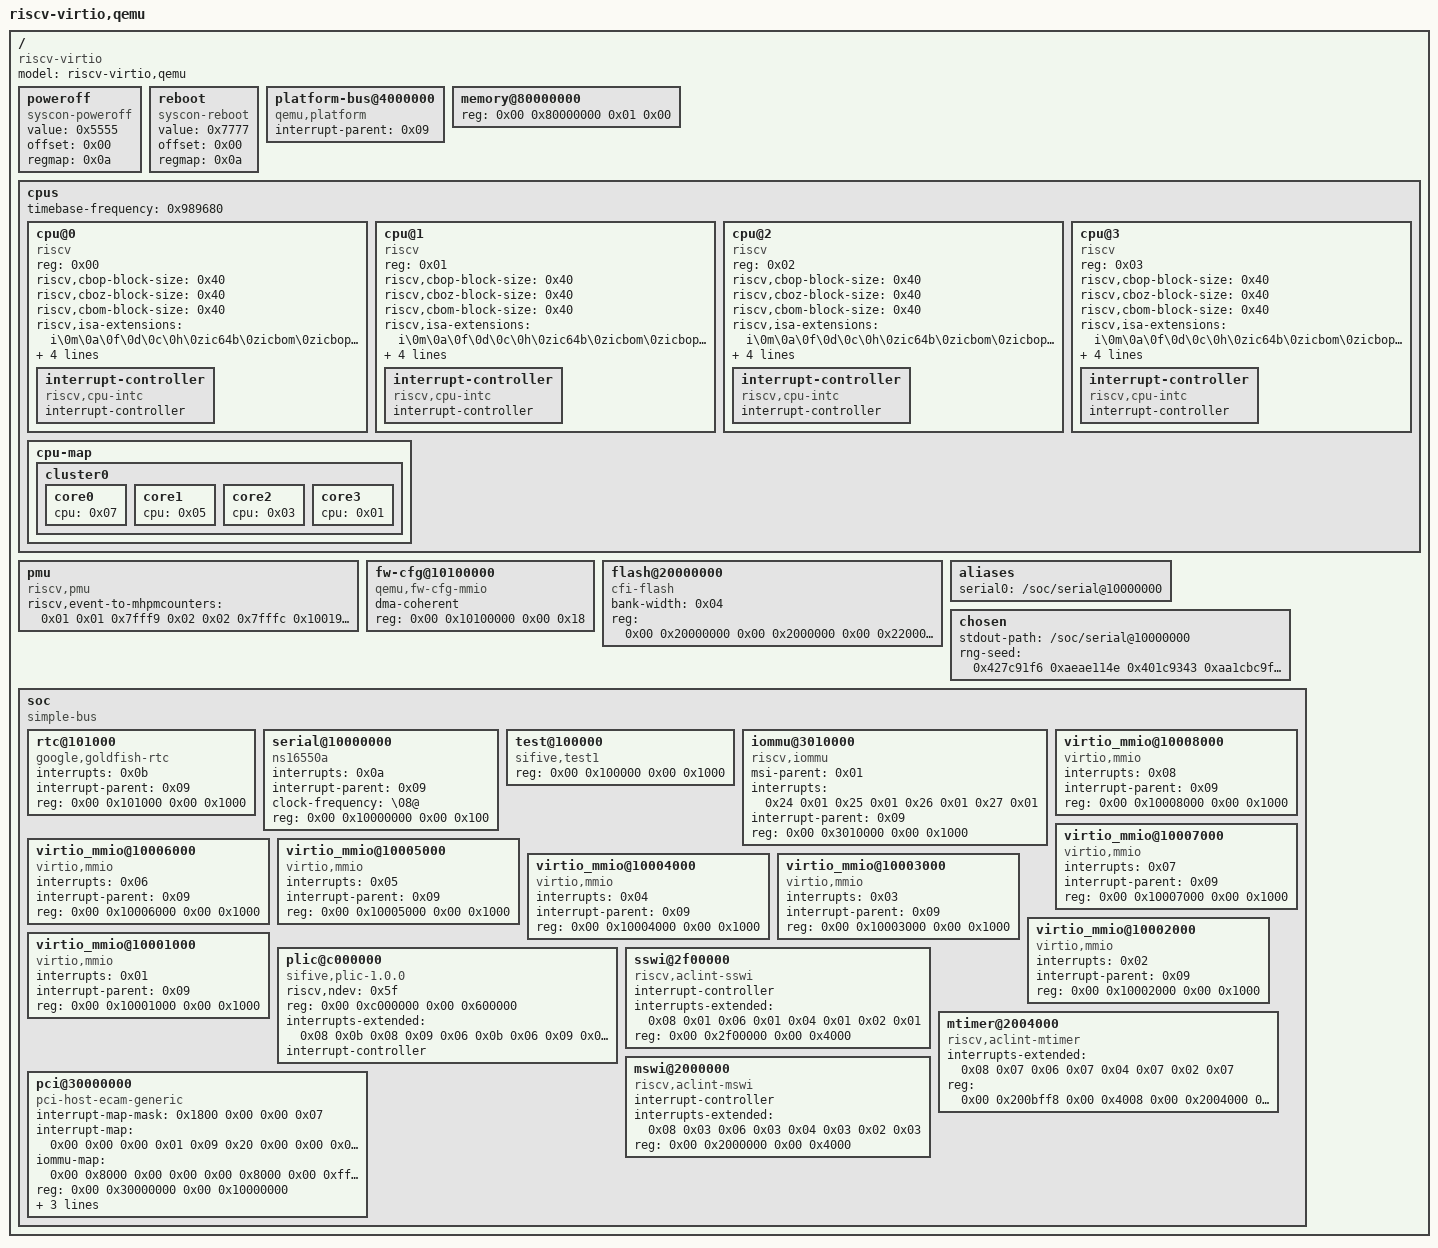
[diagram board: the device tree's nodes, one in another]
/dts-v1/;

/ {
	#address-cells = <0x02>;
	#size-cells = <0x02>;
	compatible = "riscv-virtio";
	model = "riscv-virtio,qemu";

	poweroff {
		value = <0x5555>;
		offset = <0x00>;
		regmap = <0x0a>;
		compatible = "syscon-poweroff";
	};

	reboot {
		value = <0x7777>;
		offset = <0x00>;
		regmap = <0x0a>;
		compatible = "syscon-reboot";
	};

	platform-bus@4000000 {
		interrupt-parent = <0x09>;
		ranges = <0x00 0x00 0x4000000 0x2000000>;
		#address-cells = <0x01>;
		#size-cells = <0x01>;
		compatible = "qemu,platform\0simple-bus";
	};

	memory@80000000 {
		device_type = "memory";
		reg = <0x00 0x80000000 0x01 0x00>;
	};

	cpus {
		#address-cells = <0x01>;
		#size-cells = <0x00>;
		timebase-frequency = <0x989680>;

		cpu@0 {
			phandle = <0x07>;
			device_type = "cpu";
			reg = <0x00>;
			status = "okay";
			compatible = "riscv";
			riscv,cbop-block-size = <0x40>;
			riscv,cboz-block-size = <0x40>;
			riscv,cbom-block-size = <0x40>;
			riscv,isa-extensions = "i\0m\0a\0f\0d\0c\0h\0zic64b\0zicbom\0zicbop\0zicboz\0ziccamoa\0ziccif\0zicclsm\0ziccrse\0zicntr\0zicsr\0zifencei\0zihintntl\0zihintpause\0zihpm\0zmmul\0za64rs\0zaamo\0zalrsc\0zawrs\0zfa\0zca\0zcd\0zba\0zbb\0zbc\0zbs\0sdtrig\0shcounterenw\0shgatpa\0shtvala\0shvsatpa\0shvstvala\0shvstvecd\0ssccptr\0sscounterenw\0ssstrict\0sstc\0sstvala\0sstvecd\0ssu64xl\0svadu\0svvptc";
			riscv,isa-base = "rv64i";
			riscv,isa = "rv64imafdch_zic64b_zicbom_zicbop_zicboz_ziccamoa_ziccif_zicclsm_ziccrse_zicntr_zicsr_zifencei_zihintntl_zihintpause_zihpm_zmmul_za64rs_zaamo_zalrsc_zawrs_zfa_zca_zcd_zba_zbb_zbc_zbs_sdtrig_shcounterenw_shgatpa_shtvala_shvsatpa_shvstvala_shvstvecd_ssccptr_sscounterenw_ssstrict_sstc_sstvala_sstvecd_ssu64xl_svadu_svvptc";
			mmu-type = "riscv,sv57";

			interrupt-controller {
				#interrupt-cells = <0x01>;
				interrupt-controller;
				compatible = "riscv,cpu-intc";
				phandle = <0x08>;
			};
		};

		cpu@1 {
			phandle = <0x05>;
			device_type = "cpu";
			reg = <0x01>;
			status = "okay";
			compatible = "riscv";
			riscv,cbop-block-size = <0x40>;
			riscv,cboz-block-size = <0x40>;
			riscv,cbom-block-size = <0x40>;
			riscv,isa-extensions = "i\0m\0a\0f\0d\0c\0h\0zic64b\0zicbom\0zicbop\0zicboz\0ziccamoa\0ziccif\0zicclsm\0ziccrse\0zicntr\0zicsr\0zifencei\0zihintntl\0zihintpause\0zihpm\0zmmul\0za64rs\0zaamo\0zalrsc\0zawrs\0zfa\0zca\0zcd\0zba\0zbb\0zbc\0zbs\0sdtrig\0shcounterenw\0shgatpa\0shtvala\0shvsatpa\0shvstvala\0shvstvecd\0ssccptr\0sscounterenw\0ssstrict\0sstc\0sstvala\0sstvecd\0ssu64xl\0svadu\0svvptc";
			riscv,isa-base = "rv64i";
			riscv,isa = "rv64imafdch_zic64b_zicbom_zicbop_zicboz_ziccamoa_ziccif_zicclsm_ziccrse_zicntr_zicsr_zifencei_zihintntl_zihintpause_zihpm_zmmul_za64rs_zaamo_zalrsc_zawrs_zfa_zca_zcd_zba_zbb_zbc_zbs_sdtrig_shcounterenw_shgatpa_shtvala_shvsatpa_shvstvala_shvstvecd_ssccptr_sscounterenw_ssstrict_sstc_sstvala_sstvecd_ssu64xl_svadu_svvptc";
			mmu-type = "riscv,sv57";

			interrupt-controller {
				#interrupt-cells = <0x01>;
				interrupt-controller;
				compatible = "riscv,cpu-intc";
				phandle = <0x06>;
			};
		};

		cpu@2 {
			phandle = <0x03>;
			device_type = "cpu";
			reg = <0x02>;
			status = "okay";
			compatible = "riscv";
			riscv,cbop-block-size = <0x40>;
			riscv,cboz-block-size = <0x40>;
			riscv,cbom-block-size = <0x40>;
			riscv,isa-extensions = "i\0m\0a\0f\0d\0c\0h\0zic64b\0zicbom\0zicbop\0zicboz\0ziccamoa\0ziccif\0zicclsm\0ziccrse\0zicntr\0zicsr\0zifencei\0zihintntl\0zihintpause\0zihpm\0zmmul\0za64rs\0zaamo\0zalrsc\0zawrs\0zfa\0zca\0zcd\0zba\0zbb\0zbc\0zbs\0sdtrig\0shcounterenw\0shgatpa\0shtvala\0shvsatpa\0shvstvala\0shvstvecd\0ssccptr\0sscounterenw\0ssstrict\0sstc\0sstvala\0sstvecd\0ssu64xl\0svadu\0svvptc";
			riscv,isa-base = "rv64i";
			riscv,isa = "rv64imafdch_zic64b_zicbom_zicbop_zicboz_ziccamoa_ziccif_zicclsm_ziccrse_zicntr_zicsr_zifencei_zihintntl_zihintpause_zihpm_zmmul_za64rs_zaamo_zalrsc_zawrs_zfa_zca_zcd_zba_zbb_zbc_zbs_sdtrig_shcounterenw_shgatpa_shtvala_shvsatpa_shvstvala_shvstvecd_ssccptr_sscounterenw_ssstrict_sstc_sstvala_sstvecd_ssu64xl_svadu_svvptc";
			mmu-type = "riscv,sv57";

			interrupt-controller {
				#interrupt-cells = <0x01>;
				interrupt-controller;
				compatible = "riscv,cpu-intc";
				phandle = <0x04>;
			};
		};

		cpu@3 {
			phandle = <0x01>;
			device_type = "cpu";
			reg = <0x03>;
			status = "okay";
			compatible = "riscv";
			riscv,cbop-block-size = <0x40>;
			riscv,cboz-block-size = <0x40>;
			riscv,cbom-block-size = <0x40>;
			riscv,isa-extensions = "i\0m\0a\0f\0d\0c\0h\0zic64b\0zicbom\0zicbop\0zicboz\0ziccamoa\0ziccif\0zicclsm\0ziccrse\0zicntr\0zicsr\0zifencei\0zihintntl\0zihintpause\0zihpm\0zmmul\0za64rs\0zaamo\0zalrsc\0zawrs\0zfa\0zca\0zcd\0zba\0zbb\0zbc\0zbs\0sdtrig\0shcounterenw\0shgatpa\0shtvala\0shvsatpa\0shvstvala\0shvstvecd\0ssccptr\0sscounterenw\0ssstrict\0sstc\0sstvala\0sstvecd\0ssu64xl\0svadu\0svvptc";
			riscv,isa-base = "rv64i";
			riscv,isa = "rv64imafdch_zic64b_zicbom_zicbop_zicboz_ziccamoa_ziccif_zicclsm_ziccrse_zicntr_zicsr_zifencei_zihintntl_zihintpause_zihpm_zmmul_za64rs_zaamo_zalrsc_zawrs_zfa_zca_zcd_zba_zbb_zbc_zbs_sdtrig_shcounterenw_shgatpa_shtvala_shvsatpa_shvstvala_shvstvecd_ssccptr_sscounterenw_ssstrict_sstc_sstvala_sstvecd_ssu64xl_svadu_svvptc";
			mmu-type = "riscv,sv57";

			interrupt-controller {
				#interrupt-cells = <0x01>;
				interrupt-controller;
				compatible = "riscv,cpu-intc";
				phandle = <0x02>;
			};
		};

		cpu-map {

			cluster0 {

				core0 {
					cpu = <0x07>;
				};

				core1 {
					cpu = <0x05>;
				};

				core2 {
					cpu = <0x03>;
				};

				core3 {
					cpu = <0x01>;
				};
			};
		};
	};

	pmu {
		riscv,event-to-mhpmcounters = <0x01 0x01 0x7fff9 0x02 0x02 0x7fffc 0x10019 0x10019 0x7fff8 0x1001b 0x1001b 0x7fff8 0x10021 0x10021 0x7fff8>;
		compatible = "riscv,pmu";
	};

	fw-cfg@10100000 {
		dma-coherent;
		reg = <0x00 0x10100000 0x00 0x18>;
		compatible = "qemu,fw-cfg-mmio";
	};

	flash@20000000 {
		bank-width = <0x04>;
		reg = <0x00 0x20000000 0x00 0x2000000 0x00 0x22000000 0x00 0x2000000>;
		compatible = "cfi-flash";
	};

	aliases {
		serial0 = "/soc/serial@10000000";
	};

	chosen {
		stdout-path = "/soc/serial@10000000";
		rng-seed = <0x427c91f6 0xaeae114e 0x401c9343 0xaa1cbc9f 0xc3c08a2c 0xe11a971 0x495bed69 0x77d3d696>;
	};

	soc {
		#address-cells = <0x02>;
		#size-cells = <0x02>;
		compatible = "simple-bus";
		ranges;

		rtc@101000 {
			interrupts = <0x0b>;
			interrupt-parent = <0x09>;
			reg = <0x00 0x101000 0x00 0x1000>;
			compatible = "google,goldfish-rtc";
		};

		serial@10000000 {
			interrupts = <0x0a>;
			interrupt-parent = <0x09>;
			clock-frequency = "\08@";
			reg = <0x00 0x10000000 0x00 0x100>;
			compatible = "ns16550a";
		};

		test@100000 {
			phandle = <0x0a>;
			reg = <0x00 0x100000 0x00 0x1000>;
			compatible = "sifive,test1\0sifive,test0\0syscon";
		};

		iommu@3010000 {
			msi-parent = <0x01>;
			interrupts = <0x24 0x01 0x25 0x01 0x26 0x01 0x27 0x01>;
			interrupt-parent = <0x09>;
			reg = <0x00 0x3010000 0x00 0x1000>;
			phandle = <0x8000>;
			#iommu-cells = <0x01>;
			compatible = "riscv,iommu";
		};

		virtio_mmio@10008000 {
			interrupts = <0x08>;
			interrupt-parent = <0x09>;
			reg = <0x00 0x10008000 0x00 0x1000>;
			compatible = "virtio,mmio";
		};

		virtio_mmio@10007000 {
			interrupts = <0x07>;
			interrupt-parent = <0x09>;
			reg = <0x00 0x10007000 0x00 0x1000>;
			compatible = "virtio,mmio";
		};

		virtio_mmio@10006000 {
			interrupts = <0x06>;
			interrupt-parent = <0x09>;
			reg = <0x00 0x10006000 0x00 0x1000>;
			compatible = "virtio,mmio";
		};

		virtio_mmio@10005000 {
			interrupts = <0x05>;
			interrupt-parent = <0x09>;
			reg = <0x00 0x10005000 0x00 0x1000>;
			compatible = "virtio,mmio";
		};

		virtio_mmio@10004000 {
			interrupts = <0x04>;
			interrupt-parent = <0x09>;
			reg = <0x00 0x10004000 0x00 0x1000>;
			compatible = "virtio,mmio";
		};

		virtio_mmio@10003000 {
			interrupts = <0x03>;
			interrupt-parent = <0x09>;
			reg = <0x00 0x10003000 0x00 0x1000>;
			compatible = "virtio,mmio";
		};

		virtio_mmio@10002000 {
			interrupts = <0x02>;
			interrupt-parent = <0x09>;
			reg = <0x00 0x10002000 0x00 0x1000>;
			compatible = "virtio,mmio";
		};

		virtio_mmio@10001000 {
			interrupts = <0x01>;
			interrupt-parent = <0x09>;
			reg = <0x00 0x10001000 0x00 0x1000>;
			compatible = "virtio,mmio";
		};

		plic@c000000 {
			phandle = <0x09>;
			riscv,ndev = <0x5f>;
			reg = <0x00 0xc000000 0x00 0x600000>;
			interrupts-extended = <0x08 0x0b 0x08 0x09 0x06 0x0b 0x06 0x09 0x04 0x0b 0x04 0x09 0x02 0x0b 0x02 0x09>;
			interrupt-controller;
			compatible = "sifive,plic-1.0.0\0riscv,plic0";
			#address-cells = <0x00>;
			#interrupt-cells = <0x01>;
		};

		sswi@2f00000 {
			#interrupt-cells = <0x00>;
			interrupt-controller;
			interrupts-extended = <0x08 0x01 0x06 0x01 0x04 0x01 0x02 0x01>;
			reg = <0x00 0x2f00000 0x00 0x4000>;
			compatible = "riscv,aclint-sswi";
		};

		mtimer@2004000 {
			interrupts-extended = <0x08 0x07 0x06 0x07 0x04 0x07 0x02 0x07>;
			reg = <0x00 0x200bff8 0x00 0x4008 0x00 0x2004000 0x00 0x7ff8>;
			compatible = "riscv,aclint-mtimer";
		};

		mswi@2000000 {
			#interrupt-cells = <0x00>;
			interrupt-controller;
			interrupts-extended = <0x08 0x03 0x06 0x03 0x04 0x03 0x02 0x03>;
			reg = <0x00 0x2000000 0x00 0x4000>;
			compatible = "riscv,aclint-mswi";
		};

		pci@30000000 {
			interrupt-map-mask = <0x1800 0x00 0x00 0x07>;
			interrupt-map = <0x00 0x00 0x00 0x01 0x09 0x20 0x00 0x00 0x00 0x02 0x09 0x21 0x00 0x00 0x00 0x03 0x09 0x22 0x00 0x00 0x00 0x04 0x09 0x23 0x800 0x00 0x00 0x01 0x09 0x21 0x800 0x00 0x00 0x02 0x09 0x22 0x800 0x00 0x00 0x03 0x09 0x23 0x800 0x00 0x00 0x04 0x09 0x20 0x1000 0x00 0x00 0x01 0x09 0x22 0x1000 0x00 0x00 0x02 0x09 0x23 0x1000 0x00 0x00 0x03 0x09 0x20 0x1000 0x00 0x00 0x04 0x09 0x21 0x1800 0x00 0x00 0x01 0x09 0x23 0x1800 0x00 0x00 0x02 0x09 0x20 0x1800 0x00 0x00 0x03 0x09 0x21 0x1800 0x00 0x00 0x04 0x09 0x22>;
			iommu-map = <0x00 0x8000 0x00 0x00 0x00 0x8000 0x00 0xffff>;
			ranges = <0x1000000 0x00 0x00 0x00 0x3000000 0x00 0x10000 0x2000000 0x00 0x40000000 0x00 0x40000000 0x00 0x40000000 0x3000000 0x04 0x00 0x04 0x00 0x04 0x00>;
			reg = <0x00 0x30000000 0x00 0x10000000>;
			dma-coherent;
			bus-range = <0x00 0xff>;
			linux,pci-domain = <0x00>;
			device_type = "pci";
			compatible = "pci-host-ecam-generic";
			#size-cells = <0x02>;
			#interrupt-cells = <0x01>;
			#address-cells = <0x03>;
		};
	};
};
